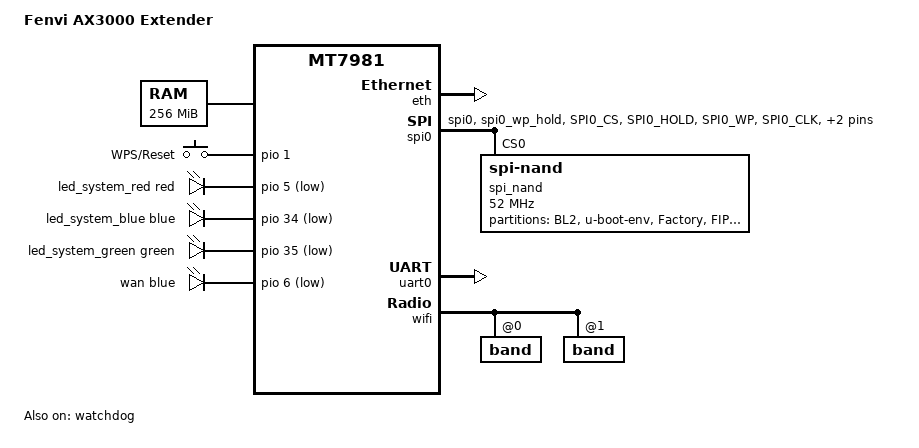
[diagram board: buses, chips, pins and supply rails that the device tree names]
/dts-v1/;

#include <dt-bindings/gpio/gpio.h>
#include <dt-bindings/input/input.h>
#include <dt-bindings/leds/common.h>

#include "mt7981b.dtsi"

/ {
	model = "Fenvi AX3000 Extender";
	compatible = "fenvi,ax3000-extender", "mediatek,mt7981";

	aliases {
		serial0 = &uart0;
		led-boot = &led_system_red;
		led-failsafe = &led_system_red;
		led-running = &led_system_green;
		led-upgrade = &led_system_blue;
		ethernet0 = &gmac1;
	};

	chosen {
		bootargs = "console=ttyS0,115200n1 loglevel=8  \
				earlycon=uart8250,mmio32,0x11002000";
		stdout-path = "serial0:115200n8";
	};

	memory@40000000 {
		reg = <0 0x40000000 0 0x10000000>;
		device_type = "memory";
	};

	gpio-keys {
		compatible = "gpio-keys";
		
		/* Single physical button on GPIO 1, Active High.
		 * Short press: WPS (handled by this keycode).
		 * Long press: Reset (handled by userspace monitoring this key).
		 */
		button_wps_reset {
			label = "WPS/Reset";
			linux,code = <KEY_WPS_BUTTON>;
			gpios = <&pio 1 GPIO_ACTIVE_HIGH>;
			debounce-interval = <60>;
		};
	};

	leds {
		compatible = "gpio-leds";

		led_system_red: red {
			color = <LED_COLOR_ID_RED>;
			function = LED_FUNCTION_STATUS;
			gpios = <&pio 5 GPIO_ACTIVE_LOW>;
			#default-state = "on";
		};

		led_system_blue: blue {
			color = <LED_COLOR_ID_BLUE>;
			function = LED_FUNCTION_STATUS;
			gpios = <&pio 34 GPIO_ACTIVE_LOW>;
		};

		led_system_green: green {
			color = <LED_COLOR_ID_GREEN>;
			function = LED_FUNCTION_STATUS;
			gpios = <&pio 35 GPIO_ACTIVE_LOW>;
		};

		wan {
			color = <LED_COLOR_ID_BLUE>;
			function = LED_FUNCTION_WAN;
			gpios = <&pio 6 GPIO_ACTIVE_LOW>;
			linux,default-trigger = "netdev";
			linux,netdev-device = "eth0";
			linux,netdev-link;
		};
	};
};

&eth {
	status = "okay";

	gmac0: mac@0 {
		compatible = "mediatek,eth-mac";
		reg = <0>;
		status = "disabled";
	};

	gmac1: mac@1 {
		compatible = "mediatek,eth-mac";
		reg = <1>;
		phy-mode = "gmii";
		phy-handle = <&int_gbe_phy>;
		
		nvmem-cell-names = "mac-address";
		nvmem-cells = <&macaddr_factory_20>;		
	};
};

&spi0 {
	pinctrl-names = "default";
	pinctrl-0 = <&spi0_flash_pins>;
	status = "okay";

	spi_nand@0 {
		#address-cells = <1>;
		#size-cells = <1>;
		compatible = "spi-nand";
		reg = <0>;
		spi-max-frequency = <52000000>;
		spi-tx-bus-width = <4>;
		spi-rx-bus-width = <4>;

		mediatek,nmbm;
		mediatek,bmt-max-ratio = <1>;
		mediatek,bmt-max-reserved-blocks = <64>;

		partitions {
			compatible = "fixed-partitions";
			#address-cells = <1>;
			#size-cells = <1>;

			partition@0 {
				label = "BL2";
				reg = <0x0 0x100000>;
				read-only;
			};

			partition@100000 {
				label = "u-boot-env";
				reg = <0x100000 0x80000>;
			};

			partition@180000 {
				label = "Factory";
				reg = <0x180000 0x200000>;
				read-only;

				nvmem-layout {
					compatible = "fixed-layout";
					#address-cells = <1>;
					#size-cells = <1>;

					eeprom_factory_0: eeprom@0 {
						reg = <0x0 0x1000>;
					};

					macaddr_factory_4: macaddr@4 {
						reg = <0x4 0x6>;
					};
					
					macaddr_factory_a: macaddr@a {
						reg = <0xa 0x6>;
					};

					macaddr_factory_20: macaddr@20 {
						reg = <0x20 0x6>;
					};					
				};
			};

			partition@380000 {
				label = "FIP";
				reg = <0x380000 0x200000>;
				read-only;
			};

			partition@580000 {
				label = "ubi";
				reg = <0x0580000 0x04000000>;
			};
		};
	};
};

&pio {

	spi0_flash_pins: spi0-pins {
		mux {
			function = "spi";
			groups = "spi0", "spi0_wp_hold";
		};
		conf-pu {
			pins = "SPI0_CS", "SPI0_HOLD", "SPI0_WP";
			drive-strength = <MTK_DRIVE_4mA>;
			bias-pull-up = <MTK_PUPD_SET_R1R0_11>;
		};
		conf-pd {
			pins = "SPI0_CLK", "SPI0_MOSI", "SPI0_MISO";
			drive-strength = <MTK_DRIVE_4mA>;
			bias-pull-down = <MTK_PUPD_SET_R1R0_11>;
		};
	};
};

&uart0 {
	status = "okay";
};

&watchdog {
	status = "okay";
};

&wifi {
	status = "okay";
	#address-cells = <1>;
	#size-cells = <0>;

	nvmem-cells = <&eeprom_factory_0>;
	nvmem-cell-names = "eeprom";

	band@0 {
		reg = <0>;
		nvmem-cell-names = "mac-address";
		nvmem-cells = <&macaddr_factory_4>;
	};

	band@1 {
		reg = <1>;
		nvmem-cell-names = "mac-address";
		nvmem-cells = <&macaddr_factory_a>;
	};
};

